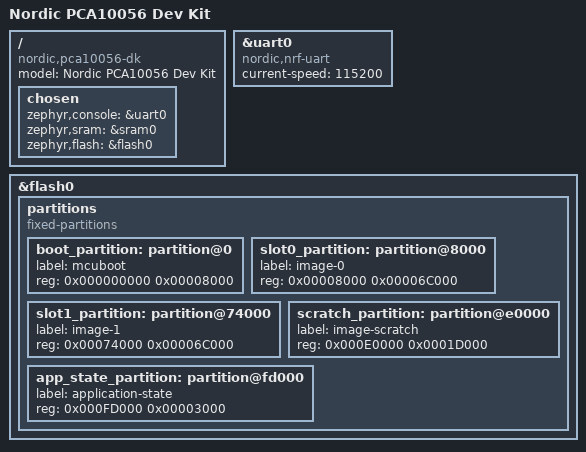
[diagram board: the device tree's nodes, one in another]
/*
 * Copyright (c) 2017 Linaro Limited
 *
 * SPDX-License-Identifier: Apache-2.0
 */

/dts-v1/;
#include <nordic/nrf52840.dtsi>

/ {
	model = "Nordic PCA10056 Dev Kit";
	compatible = "nordic,pca10056-dk", "nordic,nrf52840-qiaa",
		     "nordic,nrf52840";

	chosen {
		zephyr,console = &uart0;
		zephyr,sram = &sram0;
		zephyr,flash = &flash0;
	};
};

&uart0 {
	compatible = "nordic,nrf-uart";
	current-speed = <115200>;
	status = "ok";
};

&flash0 {
	partitions {
		compatible = "fixed-partitions";
		#address-cells = <1>;
		#size-cells = <1>;

		boot_partition: partition@0 {
			label = "mcuboot";
			reg = <0x000000000 0x00008000>;
		};
		slot0_partition: partition@8000 {
			label = "image-0";
			reg = <0x00008000 0x00006C000>;
		};
		slot1_partition: partition@74000 {
			label = "image-1";
			reg = <0x00074000 0x00006C000>;
		};
		scratch_partition: partition@e0000 {
			label = "image-scratch";
			reg = <0x000E0000 0x0001D000>;
		};
		app_state_partition: partition@fd000 {
			label = "application-state";
			reg = <0x000FD000 0x00003000>;
		};
	};
};
